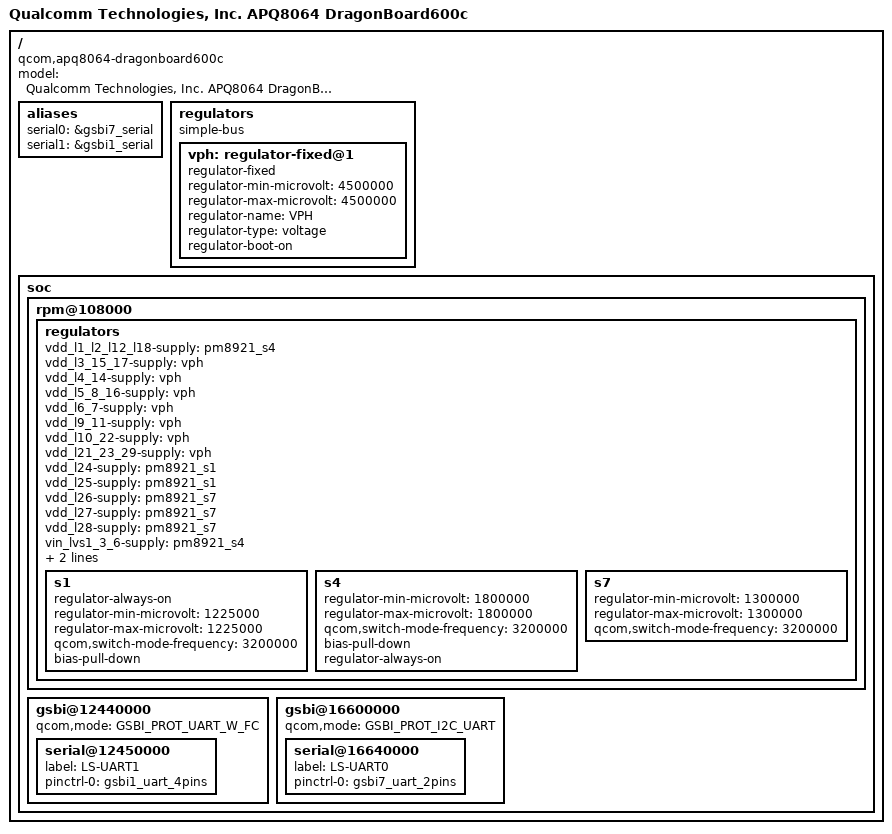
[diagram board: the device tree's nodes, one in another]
#include "qcom-apq8064-v2.0.dtsi"

/ {
	model = "Qualcomm Technologies, Inc. APQ8064 DragonBoard600c";
	compatible = "qcom,apq8064-dragonboard600c", "qcom,apq8064";

	aliases {
		serial0 = &gsbi7_serial;
		serial1 = &gsbi1_serial;
	};

	regulators {
		compatible = "simple-bus";
		vph: regulator-fixed@1 {
			compatible = "regulator-fixed";
			regulator-min-microvolt = <4500000>;
			regulator-max-microvolt = <4500000>;
			regulator-name = "VPH";
			regulator-type = "voltage";
			regulator-boot-on;
		};
	};

	soc {
		rpm@108000 {
			regulators {
				vdd_l1_l2_l12_l18-supply = <&pm8921_s4>;
				vdd_l3_15_17-supply = <&vph>;
				vdd_l4_14-supply = <&vph>;
				vdd_l5_8_16-supply = <&vph>;
				vdd_l6_7-supply = <&vph>;
				vdd_l9_11-supply = <&vph>;
				vdd_l10_22-supply = <&vph>;
				vdd_l21_23_29-supply = <&vph>;
				vdd_l24-supply = <&pm8921_s1>;
				vdd_l25-supply = <&pm8921_s1>;
				vdd_l26-supply = <&pm8921_s7>;
				vdd_l27-supply = <&pm8921_s7>;
				vdd_l28-supply = <&pm8921_s7>;
				vin_lvs1_3_6-supply = <&pm8921_s4>;
				vin_lvs2-supply = <&pm8921_s1>;
				vin_lvs4_5_7-supply = <&pm8921_s4>;

				s1 {
					regulator-always-on;
					regulator-min-microvolt = <1225000>;
					regulator-max-microvolt = <1225000>;
					qcom,switch-mode-frequency = <3200000>;
					bias-pull-down;
				};

				s4 {
					regulator-min-microvolt	= <1800000>;
					regulator-max-microvolt	= <1800000>;
					qcom,switch-mode-frequency = <3200000>;
					bias-pull-down;
					regulator-always-on;
				};

				s7 {
					regulator-min-microvolt = <1300000>;
					regulator-max-microvolt = <1300000>;
					qcom,switch-mode-frequency = <3200000>;
				 };
			};
		};

		gsbi@12440000 {
			status = "okay";
			qcom,mode = <GSBI_PROT_UART_W_FC>;
			serial@12450000 {
				label = "LS-UART1";
				status = "okay";
				pinctrl-names = "default";
				pinctrl-0 = <&gsbi1_uart_4pins>;
			};
		};

		/* DEBUG UART  */
		gsbi@16600000 {
			status = "okay";
			qcom,mode = <GSBI_PROT_I2C_UART>;
			serial@16640000 {
				label = "LS-UART0";
				status = "okay";
				pinctrl-names = "default";
				pinctrl-0 = <&gsbi7_uart_2pins>;
			};
		};
	};
};
